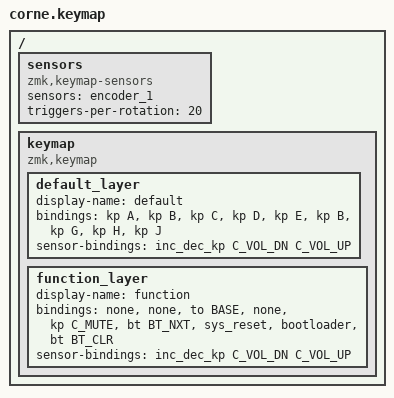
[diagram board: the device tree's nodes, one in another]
/*
 * Copyright (c) 2022 The ZMK Contributors
 *
 * SPDX-License-Identifier: MIT
 */

#include <behaviors.dtsi>
#include <dt-bindings/zmk/bt.h>
#include <dt-bindings/zmk/keys.h>

#define BASE        0
#define FUNC        1

/ {
    sensors: sensors {
        compatible = "zmk,keymap-sensors";
        sensors = <&encoder_1>;
        triggers-per-rotation = <20>;
    };

    keymap {
        compatible = "zmk,keymap";

        default_layer {
            // ---------------------------//
            // | ESC  | SPACE | Layer 2 | //
            // | BSPC | UP    |  ENTER  | //
            // | LEFT | DOWN  | RIGHT   | //

            display-name = "default";
            bindings = <
&kp A  &kp B  &kp C  &kp D  &kp E  &kp B    &kp G  &kp H  &kp J
            >;

            sensor-bindings = <&inc_dec_kp C_VOL_DN  C_VOL_UP>;
        };

        function_layer {
            // --------------------------- //
            // | none | none | Layer 2 |   //
            // | none | MUTE |  bt_nxt   |   //
            // | reset | boot | bt_clr |   //

            display-name = "function";
            bindings = <
&none  &none  &to BASE  &none  &kp C_MUTE  &bt BT_NXT    &sys_reset  &bootloader  &bt BT_CLR
            >;

            sensor-bindings = <&inc_dec_kp C_VOL_DN  C_VOL_UP>;
        };
    };
};
